# K32W061 register map
Vendor: nxp.com; File version: 1.0
CPU: CM4 r0p1, little endian, MPU, no FPU, VTOR, 3 interrupt priority bits
Registers are 32-bit, read-write, reset 0x0 unless marked. A register's access mark holds for its fields unless they carry their own. Offsets are from the block's base; [hi:lo] are bit positions; {n}, {i} and the like mark numbered series; 'fields as' and 'values as' point back to an identical list; <NAME> marks a mode.

## SYSCON (part 2 of 2) — This is the description of component syscon. It is the System Control APB bus interface. More details will follow.
Base 0x40000000
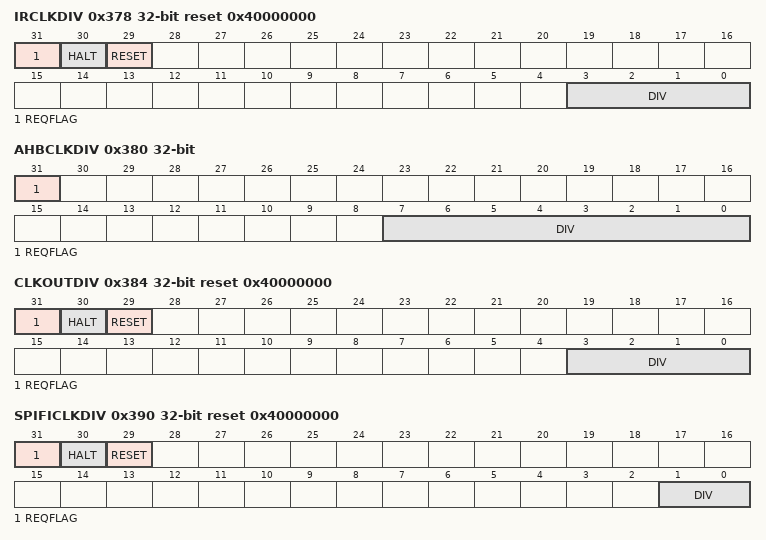
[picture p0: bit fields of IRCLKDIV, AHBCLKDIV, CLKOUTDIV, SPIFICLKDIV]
0x378 IRCLKDIV reset 0x40000000 — Infra Red clock divider
  [31] REQFLAG ro — Divider status flag. Set when a change is made to the divider value, cleared when the change is complete.
  [30] HALT — Halts the divider counter. The intent is to allow the divider s clock source to be changed without the risk of a glitch at the output.
  [29] RESET — Resets the divider counter. Can be used to make sure a new divider value is used right away rather than completing the previous count.
  [3:0] DIV — Clock divider setting, divider ratio is (DIV+1). E.g. 0: Divide by 1 and 15: Divide by 16.
0x380 AHBCLKDIV — System clock divider
  [31] REQFLAG ro — Divider status flag. Set when a change is made to the divider value, cleared when the change is complete.
  [7:0] DIV — Clock divider setting, divider ratio is (DIV+1). E.g. 0: Divide by 1 and 255: Divide by 256.
0x384 CLKOUTDIV reset 0x40000000 — CLKOUT clock divider
  fields as IRCLKDIV
0x390 SPIFICLKDIV reset 0x40000000 — SPIFI clock divider
  [31] REQFLAG ro — Divider status flag. Set when a change is made to the divider value, cleared when the change is complete.
  [30] HALT — Halts the divider counter. The intent is to allow the divider s clock source to be changed without the risk of a glitch at the output.
  [29] RESET — Resets the divider counter. Can be used to make sure a new divider value is used right away rather than completing the previous count.
  [1:0] DIV — Clock divider setting, divider ratio is (DIV+1). E.g. 0: Divide by 1 and 3: Divide by 4.
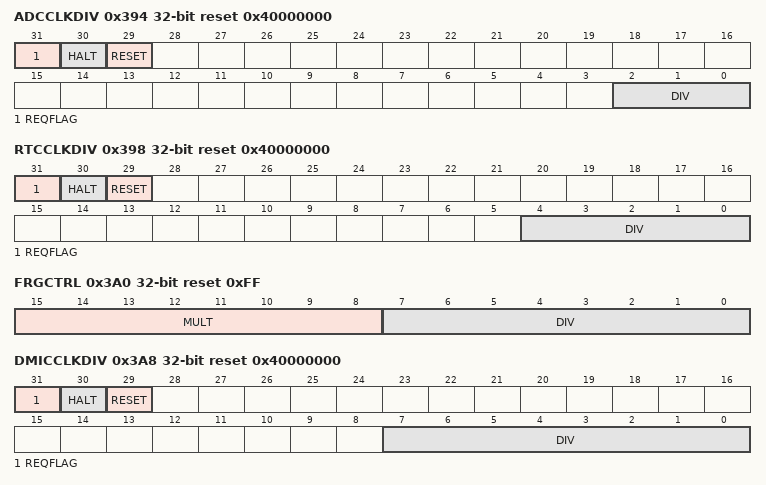
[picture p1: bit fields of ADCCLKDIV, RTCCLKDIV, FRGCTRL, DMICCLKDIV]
0x394 ADCCLKDIV reset 0x40000000 — ADC clock divider
  [31] REQFLAG ro — Divider status flag. Set when a change is made to the divider value, cleared when the change is complete.
  [30] HALT — Halts the divider counter. The intent is to allow the divider s clock source to be changed without the risk of a glitch at the output.
  [29] RESET — Resets the divider counter. Can be used to make sure a new divider value is used right away rather than completing the previous count.
  [2:0] DIV — Clock divider setting, divider ratio is (DIV+1). E.g. 0: Divide by 1 and 7: Divide by 8.
0x398 RTCCLKDIV reset 0x40000000 — Real Time Clock divider (1 KHz clock generation)
  [31] REQFLAG ro — Divider status flag. Set when a change is made to the divider value, cleared when the change is complete.
  [30] HALT — Halts the divider counter. The intent is to allow the divider s clock source to be changed without the risk of a glitch at the output.
  [29] RESET — Resets the divider counter. Can be used to make sure a new divider value is used right away rather than completing the previous count.
  [4:0] DIV — Clock divider setting, divider ratio is (DIV+1). E.g. 0: Divide by 1 and 31: Divide by 32.
0x3A0 FRGCTRL reset 0xFF — Fractional rate generator divider. The FRG is one of the USART clocking options.
  [15:8] MULT — Numerator of the fractional divider. MULT is equal to the programmed value
  [7:0] DIV — Denominator of the fractional divider is equal to the (DIV+1). Always set to 0xFF to use with the fractional baud rate generator : fout = fin / (1 + MULT/(DIV+1))
0x3A8 DMICCLKDIV reset 0x40000000 — DMIC clock divider
  [31] REQFLAG ro — Divider status flag. Set when a change is made to the divider value, cleared when the change is complete.
  [30] HALT — Halts the divider counter. The intent is to allow the divider s clock source to be changed without the risk of a glitch at the output.
  [29] RESET — Resets the divider counter. Can be used to make sure a new divider value is used right away rather than completing the previous count.
  [7:0] DIV — Clock divider setting, divider ratio is (DIV+1). E.g. 0: Divide by 1 and 255: Divide by 256.
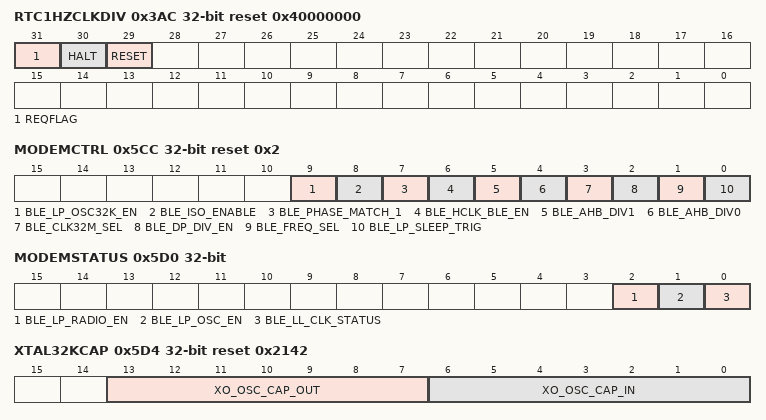
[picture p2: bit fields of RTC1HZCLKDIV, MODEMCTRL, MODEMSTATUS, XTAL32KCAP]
0x3AC RTC1HZCLKDIV reset 0x40000000 — Real Time Clock divider (1 Hz clock generation. The divider is fixed to 32768)
  [31] REQFLAG ro — Divider status flag. Set when a change is made to the divider value, cleared when the change is complete.
  [30] HALT — Halts the divider counter. The intent is to allow the divider s clock source to be changed without the risk of a glitch at the output.
  [29] RESET — Resets the divider counter. Can be used to make sure a new divider value is used right away rather than completing the previous count.
0x3FC CLOCKGENUPDATELOCKOUT — Control clock configuration registers access (like xxxDIV, xxxSEL)
  [0] LOCK — When set, disables access to clock control registers (like xxxDIV, xxxSEL). Affects all clock control registers except OSC32CLKSEL.
0x59C RNGCLKCTRL — Random Number Generator Clocks control
  [0] ENABLE — Enable the clocks used by the Random Number Generator (RNG)
0x5A0 SRAMCTRL — All SRAMs common control signals
  [1:0] SMB
0x5CC MODEMCTRL reset 0x2 — Modem (Bluetooth) control and 32K clock enable
  [9] BLE_LP_OSC32K_EN — 1 = enable the 32K clock to the BLE Low power wake up counter, USART 0 & 1, LSPI0 & 1, PMC and the frequency measure block
  [8] BLE_ISO_ENABLE — Control isolation of BLE Low Power Control module. When the BLE low power controller/timers is being used then the isolation must be enabled before entering power down state. Must not be set before MODEMSTATUS.BLE_LL_CLK_STATUS is high ('1'). 0: isolation is disabled. 1: isolation is enabled.
  [7] BLE_PHASE_MATCH_1 — For normal BLE operation set to 0. BLE operation with this bit set to 1 is not supported.
  [6] BLE_HCLK_BLE_EN — For normal BLE operation set to 1 to enable the register interface clock
  [5] BLE_AHB_DIV1 — For normal BLE operation set to 0. BLE operation with this bit set to 1 is not supported.
  [4] BLE_AHB_DIV0 — For normal BLE operation set to 0. BLE operation with this bit set to 1 is not supported.
  [3] BLE_CLK32M_SEL — For normal BLE operation set to 0. BLE operation with this bit set to 1 is not supported.
  [2] BLE_DP_DIV_EN — For normal BLE operation set to 1. BLE operation with this bit set to 0 is not supported.
  [1] BLE_FREQ_SEL — For normal BLE operation set to 1. BLE operation with this bit set to 0 is not supported. 1 = 16 MHz ; 0 = 8 MHz
  [0] BLE_LP_SLEEP_TRIG — For normal operation leave at 0. If set to 1 will cause the load of register in the BLE low power timing block, as if going into deep sleep. This is not needed for the standard method to enter power down modes.
0x5D0 MODEMSTATUS ro — Modem (Bluetooth) status
  [2] BLE_LP_RADIO_EN — BLE low power timing block can be configured to start the radio early; this is not supoorted in this device. However, that control signal can be observed here.
  [1] BLE_LP_OSC_EN — BLE low power timing block can be configured to start the wake-up sequence from power down. This status bit indicates the value of that control bit.
  [0] BLE_LL_CLK_STATUS — Status bit to indicate the clocking status from the link layer. 1 = BLE IP in deep sleep using low power clock; 0 BLE IP active using 32M clocks
0x5D4 XTAL32KCAP reset 0x2142 — XTAL 32 KHz oscillator Capacitor control
  [13:7] XO_OSC_CAP_OUT — Internal Capacitor setting for XTAL_32K_N. This setting selects the internal capacitance, to ground, that is connected to this XTAL pin. During device testing the capacitor banks are calibrated so accurate setting of the capacitance can be achieved. Software function are provided to support the setting of this register. Capacitance range is to apporximately 24pF.
  [6:0] XO_OSC_CAP_IN — Internal Capacitor setting for XTAL_32K_P. This setting selects the internal capacitance, to ground, that is connected to this XTAL pin. During device testing the capacitor banks are calibrated so accurate setting of the capacitance can be achieved. Software function are provided to support the setting of this register. Capacitance range is to apporximately 24pF.
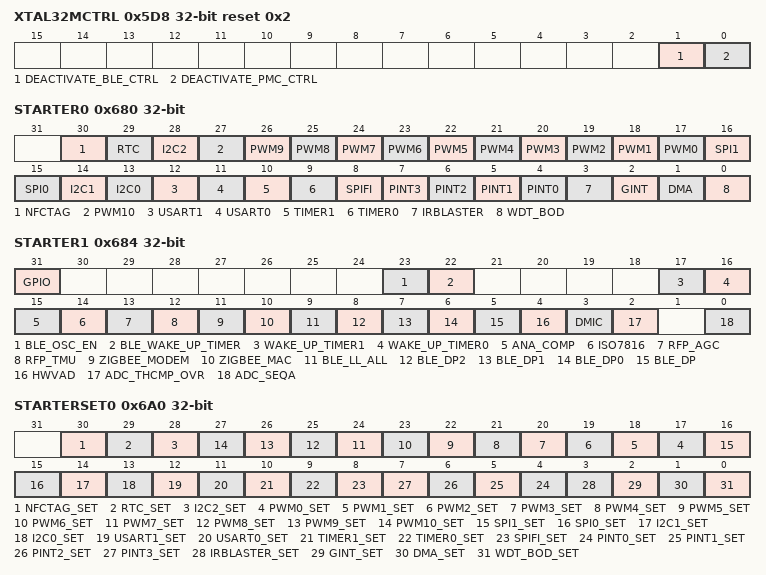
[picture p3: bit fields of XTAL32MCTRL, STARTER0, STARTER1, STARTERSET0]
0x5D8 XTAL32MCTRL reset 0x2 — XTAL 32 MHz oscillator control register
  [1] DEACTIVATE_BLE_CTRL — In order to have XTAL ready for BLE after a low power cycle the XTAL must be started early by the BLE low power module; this can be deactivated. 0: Enable XTAL 32 MHz controls coming from BLE Low Power Control module. 1: Disable XTAL 32 MHz controls coming from BLE Low Power Control module.
  [0] DEACTIVATE_PMC_CTRL — The 32MHz XTAL is enabled whenever the device is active due to internal control signals from the PMC. This control bit can deactivate this. 0: Enable XTAL 32 MHz controls coming from PMC. 1: Disable XTAL 32 MHz controls coming from PMC.
0x680 STARTER0 (STARTER view) — Start logic 0 wake-up enable register. Enable an interrupt for wake-up from deep-sleep mode. Some bits can also control wake-up from powerdown mode
  [30] NFCTAG — NFC Tag interrupt wake-up. 0 = Wake-up disabled. 1 = Wake-up enabled. Valid from Deep-Sleep. Only supported on devices with internal NFC tag.
  [29] RTC — Real Time Clock (RTC) interrupt wake-up. 0 = Wake-up disabled. 1 = Wake-up enabled. Valid from Deep-Sleep and Powerdown.
  [28] I2C2 — I2C2 interrupt wake-up. 0 = Wake-up disabled. 1 = Wake-up enabled. Valid from Deep-Sleep.
  [n+17] PWM{n} (n=0..10) — PWM{n} interrupt wake-up. 0 = Wake-up disabled. 1 = Wake-up enabled. Valid from Deep-Sleep.
  [16] SPI1 — SPI1 interrupt wake-up. 0 = Wake-up disabled. 1 = Wake-up enabled. Valid from Deep-Sleep.
  [15] SPI0 — SPI0 interrupt wake-up. 0 = Wake-up disabled. 1 = Wake-up enabled. Valid from Deep-Sleep and Powerdown.
  [14] I2C1 — I2C1 interrupt wake-up. 0 = Wake-up disabled. 1 = Wake-up enabled. Valid from Deep-Sleep.
  [13] I2C0 — I2C0 interrupt wake-up. 0 = Wake-up disabled. 1 = Wake-up enabled. Valid from Deep-Sleep and Powerdown.
  [12] USART1 — USART1 interrupt wake-up. 0 = Wake-up disabled. 1 = Wake-up enabled. Valid from Deep-Sleep.
  [11] USART0 — USART0 interrupt wake-up. 0 = Wake-up disabled. 1 = Wake-up enabled. Valid from Deep-Sleep and Powerdown.
  [10] TIMER1 — Counter/Timer1 interrupt wake-up. 0 = Wake-up disabled. 1 = Wake-up enabled. Valid from Deep-Sleep.
  [9] TIMER0 — Counter/Timer0 interrupt wake-up. 0 = Wake-up disabled. 1 = Wake-up enabled. Valid from Deep-Sleep.
  [8] SPIFI — SPI Flash Interface (SPIFI) interrupt wake-up. 0 = Wake-up disabled. 1 = Wake-up enabled. Valid from Deep-Sleep.
  [n+4] PINT{n} (n=0..3) — Pattern Interupt {n} (PINT{n}) interrupt wake-up. 0 = Wake-up disabled. 1 = Wake-up enabled. Valid from Deep-Sleep.
  [3] IRBLASTER — Infra Red Blaster interrupt wake-up. 0 = Wake-up disabled. 1 = Wake-up enabled. Valid from Deep-Sleep.
  [2] GINT — Group Interrupt 0 (GINT0) interrupt wake-up. 0 = Wake-up disabled. 1 = Wake-up enabled. Valid from Deep-Sleep.
  [1] DMA — DMA Operation in Deep-Sleep and Powerdown not supported. Leave set to 0.
  [0] WDT_BOD — WWDT and BOD Interrupt wake-up. 0 = Wake-up disabled. 1 = Wake-up enabled. Valid from Deep-Sleep and Powerdown.
0x680 STARTERS0 reset 0xFFFFFFFF (STARTER view) — Pin assign register
  [31:0] DATA
0x684 STARTER1 (STARTER view) — Start logic 1 wake-up enable register. Enable an interrupt for wake-up from deep-sleep mode. Some bits can also control wake-up from powerdown mode
  [31] GPIO — GPIO interrupt wake-up. 0 = Wake-up disabled. 1 = Wake-up enabled. Set this bit to allow GPIO or NTAG_INT to cause a wake-up in Deep-Sleep and Power-down mode.
  [23] BLE_OSC_EN — BLE Oscillator Enable interrupt wake-up. 0 = Wake-up disabled. 1 = Wake-up enabled. Valid from Deep-Sleep and Powerdown. Used as early wake-up trigger to allow 32M XTAL to be started and ready for BLE timeslot
  [22] BLE_WAKE_UP_TIMER — BLE Wake-up Timer interrupt wake-up. 0 = Wake-up disabled. 1 = Wake-up enabled. Valid from Deep-Sleep and Powerdown.
  [17] WAKE_UP_TIMER1 — Wake-up Timer1 interrupt wake-up. 0 = Wake-up disabled. 1 = Wake-up enabled. Valid from Deep-Sleep and Powerdown.
  [16] WAKE_UP_TIMER0 — Wake-up Timer0 interrupt wake-up. 0 = Wake-up disabled. 1 = Wake-up enabled. Valid from Deep-Sleep and Powerdown.
  [15] ANA_COMP — Analog Comparator interrupt wake-up. 0 = Wake-up disabled. 1 = Wake-up enabled. Valid from Deep-Sleep and Powerdown.
  [14] ISO7816 — ISO7816 Smart Card interface interrupt wake-up. 0 = Wake-up disabled. 1 = Wake-up enabled. Valid from Deep-Sleep.
  [13] RFP_AGC — Radio Control AGC (RFP AGC) interrupt wake-up. 0 = Wake-up disabled. 1 = Wake-up enabled. Valid from Deep-Sleep.
  [12] RFP_TMU — Radio Controller Timing Controller (RFP TMU) interrupt wake-up. 0 = Wake-up disabled. 1 = Wake-up enabled. Valid from Deep-Sleep.
  [11] ZIGBEE_MODEM — Zigbee Modem interrupt wake-up. 0 = Wake-up disabled. 1 = Wake-up enabled. Valid from Deep-Sleep.
  [10] ZIGBEE_MAC — Zigbee MAC interrupt wake-up. 0 = Wake-up disabled. 1 = Wake-up enabled. Valid from Deep-Sleep.
  [9] BLE_LL_ALL — BLE Link Layer interrupt wake-up. 0 = Wake-up disabled. 1 = Wake-up enabled. Valid from Deep-Sleep.
  [8] BLE_DP2 — BLE Datapath 2 interrupt wake-up. 0 = Wake-up disabled. 1 = Wake-up enabled. Valid from Deep-Sleep.
  [7] BLE_DP1 — BLE Datapath 1 interrupt wake-up. 0 = Wake-up disabled. 1 = Wake-up enabled. Valid from Deep-Sleep.
  [6] BLE_DP0 — BLE Datapath 0 interrupt wake-up. 0 = Wake-up disabled. 1 = Wake-up enabled. Valid from Deep-Sleep.
  [5] BLE_DP — BLE Datapath interrupt wake-up. 0 = Wake-up disabled. 1 = Wake-up enabled. Valid from Deep-Sleep.
  [4] HWVAD — Hardware Voice Activity Detector (HWVAD) interrupt wake-up. 0 = Wake-up disabled. 1 = Wake-up enabled. Valid from Deep-Sleep.
  [3] DMIC — Digital Microphone (DMIC) interrupt wake-up. 0 = Wake-up disabled. 1 = Wake-up enabled. Valid from Deep-Sleep.
  [2] ADC_THCMP_OVR — ADC threshold and error interrupt wake-up. 0 = Wake-up disabled. 1 = Wake-up enabled. Valid from Deep-Sleep.
  [0] ADC_SEQA — ADC Sequence A interrupt wake-up. 0 = Wake-up disabled. 1 = Wake-up enabled. Valid from Deep-Sleep.
0x684 STARTERS1 reset 0xFFFFFFFF (STARTER view) — Pin assign register
  [31:0] DATA
0x6A0 STARTERSET0 reset not defined (STARTERSET view) — Set bits in STARTER0
  [30] NFCTAG_SET wo — Writing one to this bit sets the corresponding bit in the STARTER0 register
  [29] RTC_SET wo — Writing one to this bit sets the corresponding bit in the STARTER0 register
  [28] I2C2_SET wo — Writing one to this bit sets the corresponding bit in the STARTER0 register
  [n+17] PWM{n}_SET wo (n=0..10) — Writing one to this bit sets the corresponding bit in the STARTER0 register
  [16] SPI1_SET wo — Writing one to this bit sets the corresponding bit in the STARTER0 register
  [15] SPI0_SET wo — Writing one to this bit sets the corresponding bit in the STARTER0 register
  [14] I2C1_SET wo — Writing one to this bit sets the corresponding bit in the STARTER0 register
  [13] I2C0_SET wo — Writing one to this bit sets the corresponding bit in the STARTER0 register
  [12] USART1_SET wo — Writing one to this bit sets the corresponding bit in the STARTER0 register
  [11] USART0_SET wo — Writing one to this bit sets the corresponding bit in the STARTER0 register
  [10] TIMER1_SET wo — Writing one to this bit sets the corresponding bit in the STARTER0 register
  [9] TIMER0_SET wo — Writing one to this bit sets the corresponding bit in the STARTER0 register
  [8] SPIFI_SET wo — Writing one to this bit sets the corresponding bit in the STARTER0 register
  [n+4] PINT{n}_SET wo (n=0..3) — Writing one to this bit sets the corresponding bit in the STARTER0 register
  [3] IRBLASTER_SET wo — Writing one to this bit sets the corresponding bit in the STARTER0 register
  [2] GINT_SET wo — Writing one to this bit sets the corresponding bit in the STARTER0 register
  [1] DMA_SET wo — Writing one to this bit sets the corresponding bit in the STARTER0 register
  [0] WDT_BOD_SET wo — Writing one to this bit sets the corresponding bit in the STARTER0 register
0x6A0 STARTERSETS0 reset 0xFFFFFFFF (STARTERSET view) — Pin assign register
  [31:0] DATA
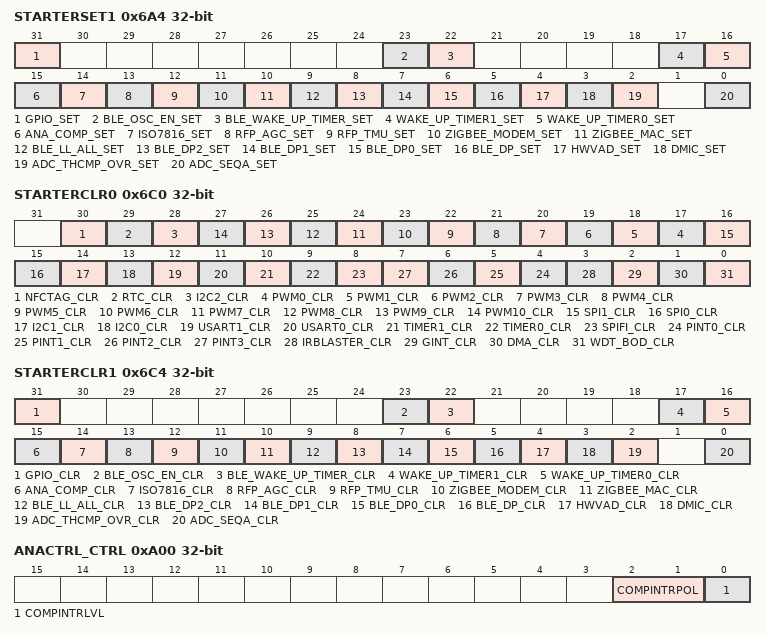
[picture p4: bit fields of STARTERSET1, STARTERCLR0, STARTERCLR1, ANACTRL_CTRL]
0x6A4 STARTERSET1 reset not defined (STARTERSET view) — Set bits in STARTER1
  [31] GPIO_SET wo — Writing one to this bit sets the corresponding bit in the STARTER1 register
  [23] BLE_OSC_EN_SET wo — Writing one to this bit sets the corresponding bit in the STARTER1 register
  [22] BLE_WAKE_UP_TIMER_SET wo — Writing one to this bit sets the corresponding bit in the STARTER1 register
  [17] WAKE_UP_TIMER1_SET wo — Writing one to this bit sets the corresponding bit in the STARTER1 register
  [16] WAKE_UP_TIMER0_SET wo — Writing one to this bit sets the corresponding bit in the STARTER1 register
  [15] ANA_COMP_SET wo — Writing one to this bit sets the corresponding bit in the STARTER1 register
  [14] ISO7816_SET wo — Writing one to this bit sets the corresponding bit in the STARTER1 register
  [13] RFP_AGC_SET wo — Writing one to this bit sets the corresponding bit in the STARTER1 register
  [12] RFP_TMU_SET wo — Writing one to this bit sets the corresponding bit in the STARTER1 register
  [11] ZIGBEE_MODEM_SET wo — Writing one to this bit sets the corresponding bit in the STARTER1 register
  [10] ZIGBEE_MAC_SET wo — Writing one to this bit sets the corresponding bit in the STARTER1 register
  [9] BLE_LL_ALL_SET wo — Writing one to this bit sets the corresponding bit in the STARTER1 register
  [8] BLE_DP2_SET wo — Writing one to this bit sets the corresponding bit in the STARTER1 register
  [7] BLE_DP1_SET wo — Writing one to this bit sets the corresponding bit in the STARTER1 register
  [6] BLE_DP0_SET wo — Writing one to this bit sets the corresponding bit in the STARTER1 register
  [5] BLE_DP_SET wo — Writing one to this bit sets the corresponding bit in the STARTER1 register
  [4] HWVAD_SET wo — Writing one to this bit sets the corresponding bit in the STARTER1 register
  [3] DMIC_SET wo — Writing one to this bit sets the corresponding bit in the STARTER1 register
  [2] ADC_THCMP_OVR_SET wo — Writing one to this bit sets the corresponding bit in the STARTER1 register
  [0] ADC_SEQA_SET wo — Writing one to this bit sets the corresponding bit in the STARTER1 register
0x6A4 STARTERSETS1 reset 0xFFFFFFFF (STARTERSET view) — Pin assign register
  [31:0] DATA
0x6C0 STARTERCLR0 reset not defined (STARTERCLR view) — Clear bits in STARTER0
  [30] NFCTAG_CLR wo — Writing one to this bit clears the corresponding bit in the STARTER0 register
  [29] RTC_CLR wo — Writing one to this bit clears the corresponding bit in the STARTER0 register
  [28] I2C2_CLR wo — Writing one to this bit clears the corresponding bit in the STARTER0 register
  [n+17] PWM{n}_CLR wo (n=0..10) — Writing one to this bit clears the corresponding bit in the STARTER0 register
  [16] SPI1_CLR wo — Writing one to this bit clears the corresponding bit in the STARTER0 register
  [15] SPI0_CLR wo — Writing one to this bit clears the corresponding bit in the STARTER0 register
  [14] I2C1_CLR wo — Writing one to this bit clears the corresponding bit in the STARTER0 register
  [13] I2C0_CLR wo — Writing one to this bit clears the corresponding bit in the STARTER0 register
  [12] USART1_CLR wo — Writing one to this bit clears the corresponding bit in the STARTER0 register
  [11] USART0_CLR wo — Writing one to this bit clears the corresponding bit in the STARTER0 register
  [10] TIMER1_CLR wo — Writing one to this bit clears the corresponding bit in the STARTER0 register
  [9] TIMER0_CLR wo — Writing one to this bit clears the corresponding bit in the STARTER0 register
  [8] SPIFI_CLR wo — Writing one to this bit clears the corresponding bit in the STARTER0 register
  [n+4] PINT{n}_CLR wo (n=0..3) — Writing one to this bit clears the corresponding bit in the STARTER0 register
  [3] IRBLASTER_CLR wo — Writing one to this bit clears the corresponding bit in the STARTER0 register
  [2] GINT_CLR wo — Writing one to this bit clears the corresponding bit in the STARTER0 register
  [1] DMA_CLR wo — Writing one to this bit clears the corresponding bit in the STARTER0 register
  [0] WDT_BOD_CLR wo — Writing one to this bit clears the corresponding bit in the STARTER0 register
0x6C0 STARTERCLRS0 reset 0xFFFFFFFF (STARTERCLR view) — Pin assign register
  [31:0] DATA
0x6C4 STARTERCLR1 reset not defined (STARTERCLR view) — Clear bits in STARTER1
  [31] GPIO_CLR wo — Writing one to this bit clears the corresponding bit in the STARTER1 register
  [23] BLE_OSC_EN_CLR wo — Writing one to this bit clears the corresponding bit in the STARTER1 register
  [22] BLE_WAKE_UP_TIMER_CLR wo — Writing one to this bit clears the corresponding bit in the STARTER1 register
  [17] WAKE_UP_TIMER1_CLR wo — Writing one to this bit clears the corresponding bit in the STARTER1 register
  [16] WAKE_UP_TIMER0_CLR wo — Writing one to this bit clears the corresponding bit in the STARTER1 register
  [15] ANA_COMP_CLR wo — Writing one to this bit clears the corresponding bit in the STARTER1 register
  [14] ISO7816_CLR wo — Writing one to this bit clears the corresponding bit in the STARTER1 register
  [13] RFP_AGC_CLR wo — Writing one to this bit clears the corresponding bit in the STARTER1 register
  [12] RFP_TMU_CLR wo — Writing one to this bit clears the corresponding bit in the STARTER1 register
  [11] ZIGBEE_MODEM_CLR wo — Writing one to this bit clears the corresponding bit in the STARTER1 register
  [10] ZIGBEE_MAC_CLR wo — Writing one to this bit clears the corresponding bit in the STARTER1 register
  [9] BLE_LL_ALL_CLR wo — Writing one to this bit clears the corresponding bit in the STARTER1 register
  [8] BLE_DP2_CLR wo — Writing one to this bit clears the corresponding bit in the STARTER1 register
  [7] BLE_DP1_CLR wo — Writing one to this bit clears the corresponding bit in the STARTER1 register
  [6] BLE_DP0_CLR wo — Writing one to this bit clears the corresponding bit in the STARTER1 register
  [5] BLE_DP_CLR wo — Writing one to this bit clears the corresponding bit in the STARTER1 register
  [4] HWVAD_CLR wo — Writing one to this bit clears the corresponding bit in the STARTER1 register
  [3] DMIC_CLR wo — Writing one to this bit clears the corresponding bit in the STARTER1 register
  [2] ADC_THCMP_OVR_CLR wo — Writing one to this bit clears the corresponding bit in the STARTER1 register
  [0] ADC_SEQA_CLR wo — Writing one to this bit clears the corresponding bit in the STARTER1 register
0x6C4 STARTERCLRS1 reset 0xFFFFFFFF (STARTERCLR view) — Pin assign register
  [31:0] DATA
0x708 RETENTIONCTRL — I/O retention control register
  [0] IOCLAMP — Global control of activation of I/O clamps to allow IOs to hold a value during a power mode cycle. To use enable before the power down and then disable after a wake up. Note that each I/O clamp must also be enabled/disabled individually in IOCON module and also that for an I2C IO cell it must be in GPIO mode for the clamping to work. 0: I/O clamp is disable 1: I/O clamp is enable
0x808 CPSTACK
0xA00 ANACTRL_CTRL — Analog Interrupt control register. Requires AHBCLKCTRL0.ANA_INT_CTRL to be set.
  [2:1] COMPINTRPOL — Analog Comparator interrupt Polarity: When COMPINTRLVL = 0 (edge sensitive): 00: rising edge. 01: falling edge. 10: both edges (rising and falling). 11: both edges (rising and falling). When COMPINTRLVL = 1 (level sensitive): 00: Low level ('0'). 01: Low level ('0'). 10: High level ('1'). 11: High level ('1').
  [0] COMPINTRLVL — Analog Comparator interrupt type: 0: Analog Comparator interrupt is edge sensitive. 1: Analog Comparator interrupt is level sensitive.
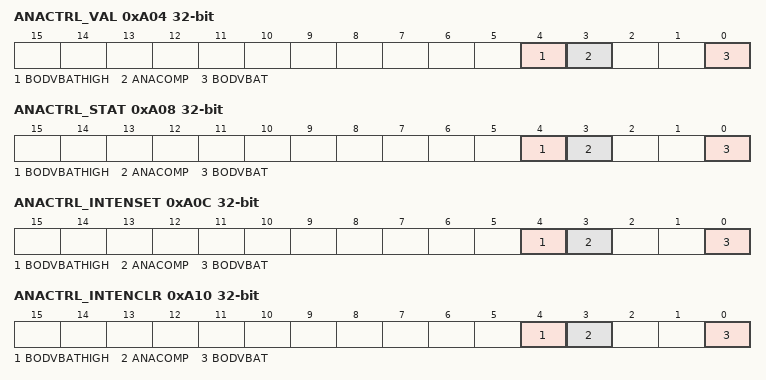
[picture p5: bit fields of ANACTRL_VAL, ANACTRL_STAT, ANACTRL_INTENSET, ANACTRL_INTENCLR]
0xA04 ANACTRL_VAL ro — Analog modules (BOD and Analog Comparator) outputs current values (BOD 'Power OK' and Analog comparator out). Requires AHBCLKCTRL0.ANA_INT_CTRL to be set.
  [4] BODVBATHIGH — Not(BOD VBAT). Inverse of BOD VBAT. 0 = Power OK; 1 = Power not OK
  [3] ANACOMP — Analog comparator Status : 0 = Comparator in 0 < in 1 ; 1 = Comparator in 0 > in 1.
  [0] BODVBAT — BOD VBAT Status : 0 = Power not OK ; 1 = Power OK
0xA08 ANACTRL_STAT — Analog modules (BOD and Analog Comparator) interrupt status. Requires AHBCLKCTRL0.ANA_INT_CTRL to be set.
  [4] BODVBATHIGH — NOT(BOD VBAT) interrupt status. Will be set when BOD VBAT goes high. Write 1 to clear.
  [3] ANACOMP — Analog comparator Interrupt status. 0: No interrupt pending. 1: Interrupt pending. Write 1 to clear.
  [0] BODVBAT — BOD VBAT Interrupt status. 0: No interrupt pending. 1: Interrupt pending. Write 1 to clear.
0xA0C ANACTRL_INTENSET — Analog modules (BOD and Analog Comparator) Interrupt Enable Read and Set register. Read value indicates which interrupts are enabled. Writing ones sets the corresponding interrupt enable bits. Note, interrupt enable bits are cleared using ANACTRL_INTENCLR. Requires AHBCLKCTRL0.ANA_INT_CTRL to be set to use this register.
  [4] BODVBATHIGH — NOT(BOD VBAT) Interrupt Enable Read and Set register
  [3] ANACOMP — Analog comparator Interrupt Enable Read and Set register
  [0] BODVBAT — BOD VBAT Interrupt Enable Read and Set register
0xA10 ANACTRL_INTENCLR reset not defined — Analog modules (BOD and Analog Comparator) Interrupt Enable Clear register. Writing ones clears the corresponding interrupt enable bits. Note, interrupt enable bits are set in ANACTRL_INTENSET. Requires AHBCLKCTRL0.ANA_INT_CTRL to be set to use this register.
  [4] BODVBATHIGH wo — NOT(BOD VBAT) Interrupt Enable Clear register
  [3] ANACOMP wo — Analog comparator Interrupt Enable Clear register
  [0] BODVBAT wo — BOD VBAT Interrupt Enable Clear register
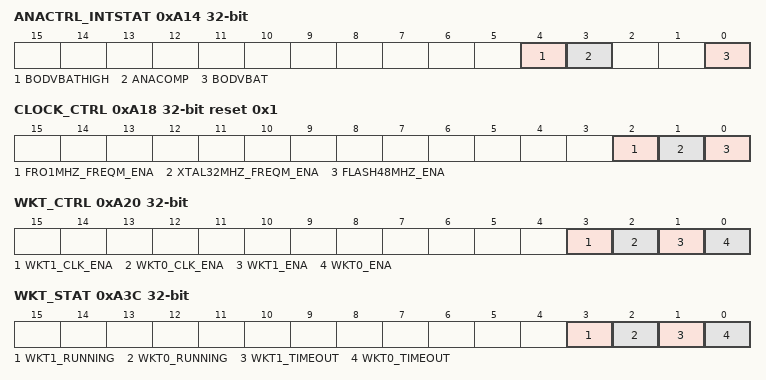
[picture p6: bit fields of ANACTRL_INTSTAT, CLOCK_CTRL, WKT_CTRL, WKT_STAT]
0xA14 ANACTRL_INTSTAT ro — Analog modules (BOD and Analog Comparator) Interrupt Status register (masked with interrupt enable). Requires AHBCLKCTRL0.ANA_INT_CTRL to be set to use this register. Interrupt status bit are cleared using ANACTRL_STAT.
  [4] BODVBATHIGH — NOT(BOD VBAT) Interrupt (after interrupt mask). 0 = No interrupt pending. 1 = Interrupt pending. Only set when BODVBATHIGH is enabled in INTENSET
  [3] ANACOMP — Analog comparator Interrupt (after interrupt mask). 0 = No interrupt pending. 1 = Interrupt pending. Only set when ANACOMP is enabled in INTENSET
  [0] BODVBAT — BOD VBAT Interrupt (after interrupt mask). 0 = No interrupt pending. 1 = Interrupt pending. Only set when BODVBAT is enabled in INTENSET
0xA18 CLOCK_CTRL reset 0x1 — Various system clock controls : Flash clock (48 MHz) control, clocks to Frequency Measure function
  [2] FRO1MHZ_FREQM_ENA — Enable FRO 1MHz clock for Frequency Measure module. 0 = Disabled. 1 = Enabled.
  [1] XTAL32MHZ_FREQM_ENA — Enable XTAL32MHz clock for Frequency Measure module. 0 = Disabled. 1 = Enabled.
  [0] FLASH48MHZ_ENA — Enable Flash 48 MHz clock. 0 = Disabled. 1 = Enabled.
0xA20 WKT_CTRL — Wake-up timers control
  [3] WKT1_CLK_ENA — Enable wake-up timer 1 clock: 0 = Disabled. 1 = Enabled.
  [2] WKT0_CLK_ENA — Enable wake-up timer 0 clock: 0 = Disabled. 1 = Enabled.
  [1] WKT1_ENA — Enable wake-up timer 1: 0 = Disabled. 1 = Enabled (counter is running).
  [0] WKT0_ENA — Enable wake-up timer 0: 0 = Disabled. 1 = Enabled (counter is running).
0xA24 WKT_LOAD_WKT0_LSB — Wake-up timer 0 reload value least significant bits ([31:0]).
  [31:0] WKT0_LOAD_LSB — Wake-up timer 0 reload value, least significant bits ([31:0]). Write when timer is not enabled
0xA28 WKT_LOAD_WKT0_MSB — Wake-up timer 0 reload value most significant bits ([8:0]).
  [8:0] WKT0_LOAD_MSB — Wake-up timer 0 reload value, most significant bits ([8:0]). Write when timer is not enabled
0xA2C WKT_LOAD_WKT1 — Wake-up timer 1 reload value.
  [27:0] WKT1_LOAD — Wake-up timer 1 reload value. Write when timer is not enabled
0xA30 WKT_VAL_WKT0_LSB ro reset 0xFFFFFFFF — Wake-up timer 0 current value least significant bits ([31:0]). WARNING : reading not reliable: read this register several times until you get a stable value.
  [31:0] WKT0_VAL_LSB — Wake-up timer 0 value, least significant bits ([31:0]). Reread until stable value seen.
0xA34 WKT_VAL_WKT0_MSB ro reset 0x1FF — Wake-up timer 0 current value most significant bits ([8:0]). WARNING : reading not reliable: read this register several times until you get a stable value.
  [8:0] WKT0_VAL_MSB — Wake-up timer 0 value, most significant bits ([8:0]). Reread until stable value seen.
0xA38 WKT_VAL_WKT1 ro reset 0xFFFFFFF — Wake-up timer 1 current value. WARNING : reading not reliable: read this register several times until you get a stable value.
  [27:0] WKT1_VAL — Wake-up timer 1 value. Reread until stable value seen.
0xA3C WKT_STAT — Wake-up timers status
  [3] WKT1_RUNNING ro — Running Status of Wake-up timer 1 : 0 = not running ; 1 = running
  [2] WKT0_RUNNING ro — Running Status of Wake-up timer 0 : 0 = not running ; 1 = running
  [1] WKT1_TIMEOUT — Timeout Status of Wake-up timer 1 : 0 = timeout not reached ; 1 = timeout reached. Write 1 to clear.
  [0] WKT0_TIMEOUT — Timeout Status of Wake-up timer 0 : 0 = timeout not reached ; 1 = timeout reached. Write 1 to clear.
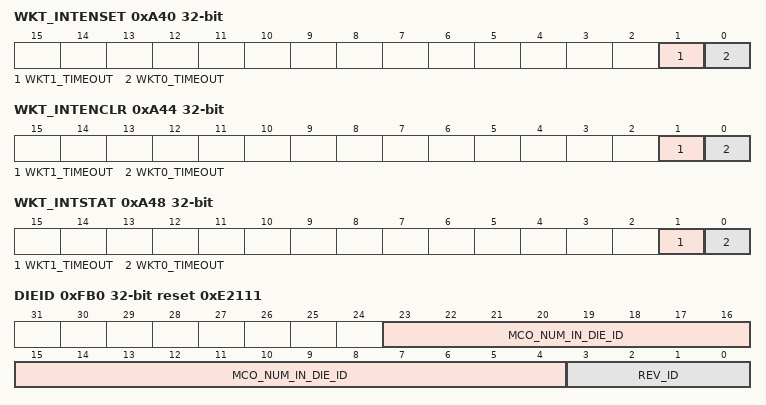
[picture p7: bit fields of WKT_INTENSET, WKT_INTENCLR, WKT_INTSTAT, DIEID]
0xA40 WKT_INTENSET — Interrupt Enable Read and Set register
  [1] WKT1_TIMEOUT — Wake-up Timer 1 Timeout Interrupt Enable Read and Set register. Read value of '1' indicates that the interrupt is enabled. Set this bit to enable the interrupt. Use WKT_INTENCLR to disable the interrupt.
  [0] WKT0_TIMEOUT — Wake-up Timer 0 Timeout Interrupt Enable Read and Set register. Read value of '1' indicates that the interrupt is enabled. Set this bit to enable the interrupt. Use WKT_INTENCLR to disable the interrupt.
0xA44 WKT_INTENCLR reset not defined — Interrupt Enable Clear register
  [1] WKT1_TIMEOUT wo — Wake-up Timer 1 Timeout Interrupt Enable Clear register. Set this bit to disable the interrupt.
  [0] WKT0_TIMEOUT wo — Wake-up Timer 0 Timeout Interrupt Enable Clear register. Set this bit to disable the interrupt.
0xA48 WKT_INTSTAT ro — Interrupt Status register
  [1] WKT1_TIMEOUT — Wake-up Timer 1 Timeout Interrupt. 0: No interrupt pending. 1: Interrupt pending. Only set when WKT1_TIMEOUT is enable in INTENSET
  [0] WKT0_TIMEOUT — Wake-up Timer 0 Timeout Interrupt. 0: No interrupt pending. 1: Interrupt pending. Only set when WKT0_TIMEOUT is enable in INTENSET
0xE08 GPIOPSYNC — Enable bypass of the first stage of synchonization inside GPIO_INT module.
  [0] PSYNC
0xFB0 DIEID ro reset 0xE2111 — Chip revision ID & Number
  [23:4] MCO_NUM_IN_DIE_ID — Chip Number
  [3:0] REV_ID — Chip Revision ID
0xFF0 CODESECURITYPROT wo reset not defined — Security code to allow test access via SWD/JTAG. Reset with POR, SW reset or BOD
  [31:0] SEC_CODE — Security code to allow debug via SWD and JTAG access in test mode. Write once register, value 0x87654321 disables the access and therefore prevents any chance to enable it. Writing any other value enables the access and locks the mode. In some cases the boot code will secure the device by writing to this register to disable SWD and JTAG. This would prevent the application being able to re-enable this access.
